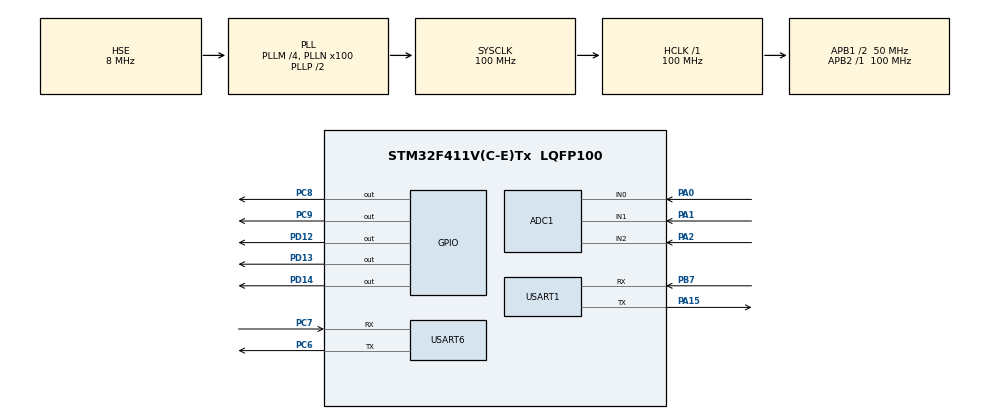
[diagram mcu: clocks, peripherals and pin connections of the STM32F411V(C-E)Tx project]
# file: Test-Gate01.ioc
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ADC1.Channel-0\#ChannelRegularConversion=ADC_CHANNEL_0
ADC1.Channel-1\#ChannelRegularConversion=ADC_CHANNEL_1
ADC1.Channel-2\#ChannelRegularConversion=ADC_CHANNEL_2
ADC1.Channel-3\#ChannelRegularConversion=ADC_CHANNEL_TEMPSENSOR
ADC1.Channel-4\#ChannelRegularConversion=ADC_CHANNEL_VREFINT
ADC1.ContinuousConvMode=ENABLE
ADC1.DMAContinuousRequests=ENABLE
ADC1.DiscontinuousConvMode=DISABLE
ADC1.NbrOfConversion=5
ADC1.NbrOfConversionFlag=1
ADC1.Rank-0\#ChannelRegularConversion=1
ADC1.Rank-1\#ChannelRegularConversion=2
ADC1.Rank-2\#ChannelRegularConversion=3
ADC1.Rank-3\#ChannelRegularConversion=4
ADC1.Rank-4\#ChannelRegularConversion=5
ADC1.SamplingTime-0\#ChannelRegularConversion=ADC_SAMPLETIME_480CYCLES
ADC1.SamplingTime-1\#ChannelRegularConversion=ADC_SAMPLETIME_480CYCLES
ADC1.SamplingTime-2\#ChannelRegularConversion=ADC_SAMPLETIME_480CYCLES
ADC1.SamplingTime-3\#ChannelRegularConversion=ADC_SAMPLETIME_480CYCLES
ADC1.SamplingTime-4\#ChannelRegularConversion=ADC_SAMPLETIME_480CYCLES
ADC1.ScanConvMode=ENABLE
ADC1.master=1
Dma.ADC1.3.Direction=DMA_PERIPH_TO_MEMORY
Dma.ADC1.3.FIFOMode=DMA_FIFOMODE_DISABLE
Dma.ADC1.3.Instance=DMA2_Stream0
Dma.ADC1.3.MemDataAlignment=DMA_MDATAALIGN_HALFWORD
Dma.ADC1.3.MemInc=DMA_MINC_ENABLE
Dma.ADC1.3.Mode=DMA_CIRCULAR
Dma.ADC1.3.PeriphDataAlignment=DMA_PDATAALIGN_HALFWORD
Dma.ADC1.3.PeriphInc=DMA_PINC_DISABLE
Dma.ADC1.3.Priority=DMA_PRIORITY_LOW
Dma.Request0=USART6_RX
Dma.Request1=USART6_TX
Dma.Request2=USART1_TX
Dma.Request3=ADC1
Dma.USART1_TX.2.Direction=DMA_MEMORY_TO_PERIPH
Dma.USART1_TX.2.FIFOMode=DMA_FIFOMODE_DISABLE
Dma.USART1_TX.2.Instance=DMA2_Stream7
Dma.USART1_TX.2.MemDataAlignment=DMA_MDATAALIGN_BYTE
Dma.USART1_TX.2.MemInc=DMA_MINC_ENABLE
Dma.USART1_TX.2.Mode=DMA_NORMAL
Dma.USART1_TX.2.PeriphDataAlignment=DMA_PDATAALIGN_BYTE
Dma.USART1_TX.2.PeriphInc=DMA_PINC_DISABLE
Dma.USART1_TX.2.Priority=DMA_PRIORITY_LOW
Dma.USART6_RX.0.Direction=DMA_PERIPH_TO_MEMORY
Dma.USART6_RX.0.FIFOMode=DMA_FIFOMODE_DISABLE
Dma.USART6_RX.0.Instance=DMA2_Stream1
Dma.USART6_RX.0.MemDataAlignment=DMA_MDATAALIGN_BYTE
Dma.USART6_RX.0.MemInc=DMA_MINC_ENABLE
Dma.USART6_RX.0.Mode=DMA_NORMAL
Dma.USART6_RX.0.PeriphDataAlignment=DMA_PDATAALIGN_BYTE
Dma.USART6_RX.0.PeriphInc=DMA_PINC_DISABLE
Dma.USART6_RX.0.Priority=DMA_PRIORITY_LOW
Dma.USART6_TX.1.Direction=DMA_MEMORY_TO_PERIPH
Dma.USART6_TX.1.FIFOMode=DMA_FIFOMODE_DISABLE
Dma.USART6_TX.1.Instance=DMA2_Stream6
Dma.USART6_TX.1.MemDataAlignment=DMA_MDATAALIGN_BYTE
Dma.USART6_TX.1.MemInc=DMA_MINC_ENABLE
Dma.USART6_TX.1.Mode=DMA_NORMAL
Dma.USART6_TX.1.PeriphDataAlignment=DMA_PDATAALIGN_BYTE
Dma.USART6_TX.1.PeriphInc=DMA_PINC_DISABLE
Dma.USART6_TX.1.Priority=DMA_PRIORITY_LOW
Mcu.Family=STM32F4
Mcu.Name=STM32F411V(C-E)Tx
Mcu.Package=LQFP100
NVIC.ADC_IRQn=true\:0\:0\:false\:false\:true\:true\:true\:true
NVIC.DMA2_Stream0_IRQn=true\:0\:0\:false\:false\:true\:false\:true\:true
NVIC.DMA2_Stream1_IRQn=true\:0\:0\:false\:false\:true\:false\:true\:true
NVIC.DMA2_Stream6_IRQn=true\:0\:0\:false\:false\:true\:false\:true\:true
NVIC.DMA2_Stream7_IRQn=true\:0\:0\:false\:false\:true\:false\:true\:true
NVIC.PriorityGroup=NVIC_PRIORITYGROUP_4
NVIC.TIM1_UP_TIM10_IRQn=true\:15\:0\:false\:false\:true\:false\:true\:true
NVIC.TimeBase=TIM1_UP_TIM10_IRQn
NVIC.TimeBaseIP=TIM1
NVIC.USART1_IRQn=true\:6\:0\:true\:false\:true\:true\:true\:true
NVIC.USART6_IRQn=true\:6\:0\:true\:false\:true\:false\:true\:true
PA0-WKUP.Signal=ADCx_IN0
PA1.Signal=ADCx_IN1
PA15.Mode=Asynchronous
PA15.Signal=USART1_TX
PA2.Signal=ADCx_IN2
PB7.Mode=Asynchronous
PB7.Signal=USART1_RX
PC6.Mode=Asynchronous
PC6.Signal=USART6_TX
PC7.Mode=Asynchronous
PC7.Signal=USART6_RX
PC8.Signal=GPIO_Output
PC9.Signal=GPIO_Output
PD12.Signal=GPIO_Output
PD13.Signal=GPIO_Output
PD14.Signal=GPIO_Output
PH0\ -\ OSC_IN.Mode=HSE-External-Oscillator
PH0\ -\ OSC_IN.Signal=RCC_OSC_IN
PH1\ -\ OSC_OUT.Mode=HSE-External-Oscillator
PH1\ -\ OSC_OUT.Signal=RCC_OSC_OUT
ProjectManager.HeapSize=0x200
ProjectManager.StackSize=0x400
ProjectManager.TargetToolchain=Makefile
RCC.48MHZClocksFreq_Value=50000000
RCC.AHBFreq_Value=100000000
RCC.APB1CLKDivider=RCC_HCLK_DIV2
RCC.APB1Freq_Value=50000000
RCC.APB1TimFreq_Value=100000000
RCC.APB2Freq_Value=100000000
RCC.APB2TimFreq_Value=100000000
RCC.CortexFreq_Value=100000000
RCC.HCLKFreq_Value=100000000
RCC.HSE_VALUE=8000000
RCC.HSI_VALUE=16000000
RCC.LSE_VALUE=32768
RCC.PLLM=4
RCC.PLLN=100
RCC.PLLSourceVirtual=RCC_PLLSOURCE_HSE
RCC.SYSCLKFreq_VALUE=100000000
RCC.SYSCLKSource=RCC_SYSCLKSOURCE_PLLCLK
RCC.VCOOutputFreq_Value=200000000
SH.ADCx_IN0.0=ADC1_IN0,IN0
SH.ADCx_IN1.0=ADC1_IN1,IN1
SH.ADCx_IN2.0=ADC1_IN2,IN2
USART1.VirtualMode=VM_ASYNC
USART6.VirtualMode=VM_ASYNC
VP_ADC1_TempSens_Input.Mode=IN-TempSens
VP_ADC1_Vref_Input.Mode=IN-Vrefint
VP_SYS_VS_tim1.Mode=TIM1
board=custom

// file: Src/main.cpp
/* USER CODE BEGIN Header */
/**
  ******************************************************************************
  * @file           : main.c
  * @brief          : Main program body
  ******************************************************************************
  * @attention
  *
  * Copyright (c) 2025 STMicroelectronics.
  * All rights reserved.
  *
  * This software is licensed under terms that can be found in the LICENSE file
  * in the root directory of this software component.
  * If no LICENSE file comes with this software, it is provided AS-IS.
  *
  ******************************************************************************
  */
/* USER CODE END Header */
#include "main.h"

/* USER CODE BEGIN Includes */
#include "task_handler.hpp"
#include "peripheral.hpp"
/* USER CODE END Includes */

ADC_HandleTypeDef hadc1;
DMA_HandleTypeDef hdma_adc1;

UART_HandleTypeDef huart1;
UART_HandleTypeDef huart6;
DMA_HandleTypeDef hdma_usart1_tx;
DMA_HandleTypeDef hdma_usart6_rx;
DMA_HandleTypeDef hdma_usart6_tx;

void SystemClock_Config(void);
static void MX_GPIO_Init(void);
static void MX_DMA_Init(void);
static void MX_USART1_UART_Init(void);
static void MX_USART6_UART_Init(void);
static void MX_ADC1_Init(void);

int main(void)
{

  /* USER CODE BEGIN 1 */
  BaseType_t status;
  /* USER CODE END 1 */

  /* MCU Configuration--------------------------------------------------------*/

  /* Reset of all peripherals, Initializes the Flash interface and the Systick. */
  HAL_Init();

  /* Configure the system clock */
  SystemClock_Config();

  /* Initialize all configured peripherals */
  MX_GPIO_Init();
  MX_DMA_Init();
  MX_USART1_UART_Init();
  MX_USART6_UART_Init();
  MX_ADC1_Init();
  /* USER CODE BEGIN 2 */
  firstInitializtion();
  /* USER CODE END 2 */

  /* Infinite loop */
  while (1)
  {

  }
}

void SystemClock_Config(void)
{
  RCC_OscInitTypeDef RCC_OscInitStruct = {0};
  RCC_ClkInitTypeDef RCC_ClkInitStruct = {0};

  /** Configure the main internal regulator output voltage
  */
  __HAL_RCC_PWR_CLK_ENABLE();
  __HAL_PWR_VOLTAGESCALING_CONFIG(PWR_REGULATOR_VOLTAGE_SCALE1);

  /** Initializes the RCC Oscillators according to the specified parameters
  * in the RCC_OscInitTypeDef structure.
  */
  RCC_OscInitStruct.OscillatorType = RCC_OSCILLATORTYPE_HSE;
  RCC_OscInitStruct.HSEState = RCC_HSE_ON;
  RCC_OscInitStruct.PLL.PLLState = RCC_PLL_ON;
  RCC_OscInitStruct.PLL.PLLSource = RCC_PLLSOURCE_HSE;
  RCC_OscInitStruct.PLL.PLLM = 4;
  RCC_OscInitStruct.PLL.PLLN = 100;
  RCC_OscInitStruct.PLL.PLLP = RCC_PLLP_DIV2;
  RCC_OscInitStruct.PLL.PLLQ = 4;
  if (HAL_RCC_OscConfig(&RCC_OscInitStruct) != HAL_OK)
  {
    Error_Handler();
  }

  /** Initializes the CPU, AHB and APB buses clocks
  */
  RCC_ClkInitStruct.ClockType = RCC_CLOCKTYPE_HCLK|RCC_CLOCKTYPE_SYSCLK
                              |RCC_CLOCKTYPE_PCLK1|RCC_CLOCKTYPE_PCLK2;
  RCC_ClkInitStruct.SYSCLKSource = RCC_SYSCLKSOURCE_PLLCLK;
  RCC_ClkInitStruct.AHBCLKDivider = RCC_SYSCLK_DIV1;
  RCC_ClkInitStruct.APB1CLKDivider = RCC_HCLK_DIV2;
  RCC_ClkInitStruct.APB2CLKDivider = RCC_HCLK_DIV1;

  if (HAL_RCC_ClockConfig(&RCC_ClkInitStruct, FLASH_LATENCY_3) != HAL_OK)
  {
    Error_Handler();
  }
}

static void MX_ADC1_Init(void)
{

  ADC_ChannelConfTypeDef sConfig = {0};

  /** Configure the global features of the ADC (Clock, Resolution, Data Alignment and number of conversion)
  */
  hadc1.Instance = ADC1;
  hadc1.Init.ClockPrescaler = ADC_CLOCK_SYNC_PCLK_DIV4;
  hadc1.Init.Resolution = ADC_RESOLUTION_12B;
  hadc1.Init.ScanConvMode = ENABLE;
  hadc1.Init.ContinuousConvMode = ENABLE;
  hadc1.Init.DiscontinuousConvMode = DISABLE;
  hadc1.Init.ExternalTrigConvEdge = ADC_EXTERNALTRIGCONVEDGE_NONE;
  hadc1.Init.ExternalTrigConv = ADC_SOFTWARE_START;
  hadc1.Init.DataAlign = ADC_DATAALIGN_RIGHT;
  hadc1.Init.NbrOfConversion = 5;
  hadc1.Init.DMAContinuousRequests = ENABLE;
  hadc1.Init.EOCSelection = ADC_EOC_SINGLE_CONV;
  if (HAL_ADC_Init(&hadc1) != HAL_OK)
  {
    Error_Handler();
  }

  /** Configure for the selected ADC regular channel its corresponding rank in the sequencer and its sample time.
  */
  sConfig.Channel = ADC_CHANNEL_0;
  sConfig.Rank = 1;
  sConfig.SamplingTime = ADC_SAMPLETIME_480CYCLES;
  if (HAL_ADC_ConfigChannel(&hadc1, &sConfig) != HAL_OK)
  {
    Error_Handler();
  }

  /** Configure for the selected ADC regular channel its corresponding rank in the sequencer and its sample time.
  */
  sConfig.Channel = ADC_CHANNEL_1;
  sConfig.Rank = 2;
  if (HAL_ADC_ConfigChannel(&hadc1, &sConfig) != HAL_OK)
  {
    Error_Handler();
  }

  /** Configure for the selected ADC regular channel its corresponding rank in the sequencer and its sample time.
  */
  sConfig.Channel = ADC_CHANNEL_2;
  sConfig.Rank = 3;
  if (HAL_ADC_ConfigChannel(&hadc1, &sConfig) != HAL_OK)
  {
    Error_Handler();
  }

  /** Configure for the selected ADC regular channel its corresponding rank in the sequencer and its sample time.
  */
  sConfig.Channel = ADC_CHANNEL_TEMPSENSOR;
  sConfig.Rank = 4;
  if (HAL_ADC_ConfigChannel(&hadc1, &sConfig) != HAL_OK)
  {
    Error_Handler();
  }

  /** Configure for the selected ADC regular channel its corresponding rank in the sequencer and its sample time.
  */
  sConfig.Channel = ADC_CHANNEL_VREFINT;
  sConfig.Rank = 5;
  if (HAL_ADC_ConfigChannel(&hadc1, &sConfig) != HAL_OK)
  {
    Error_Handler();
  }

}

static void MX_USART1_UART_Init(void)
{

  huart1.Instance = USART1;
  huart1.Init.BaudRate = 115200;
  huart1.Init.WordLength = UART_WORDLENGTH_8B;
  huart1.Init.StopBits = UART_STOPBITS_1;
  huart1.Init.Parity = UART_PARITY_NONE;
  huart1.Init.Mode = UART_MODE_TX_RX;
  huart1.Init.HwFlowCtl = UART_HWCONTROL_NONE;
  huart1.Init.OverSampling = UART_OVERSAMPLING_16;
  if (HAL_UART_Init(&huart1) != HAL_OK)
  {
    Error_Handler();
  }

}

static void MX_USART6_UART_Init(void)
{

  huart6.Instance = USART6;
  huart6.Init.BaudRate = 57600;
  huart6.Init.WordLength = UART_WORDLENGTH_8B;
  huart6.Init.StopBits = UART_STOPBITS_1;
  huart6.Init.Parity = UART_PARITY_NONE;
  huart6.Init.Mode = UART_MODE_TX_RX;
  huart6.Init.HwFlowCtl = UART_HWCONTROL_NONE;
  huart6.Init.OverSampling = UART_OVERSAMPLING_16;
  if (HAL_UART_Init(&huart6) != HAL_OK)
  {
    Error_Handler();
  }

}

static void MX_DMA_Init(void)
{

  /* DMA controller clock enable */
  __HAL_RCC_DMA2_CLK_ENABLE();

  /* DMA interrupt init */
  /* DMA2_Stream0_IRQn interrupt configuration */
  HAL_NVIC_SetPriority(DMA2_Stream0_IRQn, 6, 0);
  HAL_NVIC_EnableIRQ(DMA2_Stream0_IRQn);
  /* DMA2_Stream1_IRQn interrupt configuration */
  HAL_NVIC_SetPriority(DMA2_Stream1_IRQn, 6, 0);
  HAL_NVIC_EnableIRQ(DMA2_Stream1_IRQn);
  /* DMA2_Stream6_IRQn interrupt configuration */
  HAL_NVIC_SetPriority(DMA2_Stream6_IRQn, 6, 0);
  HAL_NVIC_EnableIRQ(DMA2_Stream6_IRQn);
  /* DMA2_Stream7_IRQn interrupt configuration */
  HAL_NVIC_SetPriority(DMA2_Stream7_IRQn, 6, 0);
  HAL_NVIC_EnableIRQ(DMA2_Stream7_IRQn);

}

static void MX_GPIO_Init(void)
{
  GPIO_InitTypeDef GPIO_InitStruct = {0};

  /* GPIO Ports Clock Enable */
  __HAL_RCC_GPIOH_CLK_ENABLE();
  __HAL_RCC_GPIOA_CLK_ENABLE();
  __HAL_RCC_GPIOD_CLK_ENABLE();
  __HAL_RCC_GPIOC_CLK_ENABLE();
  __HAL_RCC_GPIOB_CLK_ENABLE();

  /*Configure GPIO pin Output Level */
  HAL_GPIO_WritePin(GPIOD, GPIO_PIN_12|GPIO_PIN_13|GPIO_PIN_14|GPIO_PIN_15, GPIO_PIN_RESET);

  /*Configure GPIO pin Output Level */
  HAL_GPIO_WritePin(GPIOC, GPIO_PIN_8|GPIO_PIN_9, GPIO_PIN_RESET);

  /*Configure GPIO pins : PD12 PD13 PD14 */
  GPIO_InitStruct.Pin = GPIO_PIN_12|GPIO_PIN_13|GPIO_PIN_14|GPIO_PIN_15;
  GPIO_InitStruct.Mode = GPIO_MODE_OUTPUT_PP;
  GPIO_InitStruct.Pull = GPIO_NOPULL;
  GPIO_InitStruct.Speed = GPIO_SPEED_FREQ_LOW;
  HAL_GPIO_Init(GPIOD, &GPIO_InitStruct);

  /*Configure GPIO pins : PC8 PC9 */
  GPIO_InitStruct.Pin = GPIO_PIN_8|GPIO_PIN_9;
  GPIO_InitStruct.Mode = GPIO_MODE_OUTPUT_PP;
  GPIO_InitStruct.Pull = GPIO_NOPULL;
  GPIO_InitStruct.Speed = GPIO_SPEED_FREQ_LOW;
  HAL_GPIO_Init(GPIOC, &GPIO_InitStruct);

}

void HAL_TIM_PeriodElapsedCallback(TIM_HandleTypeDef *htim)
{
  if (htim->Instance == TIM1) {
    HAL_IncTick();
  }
}

void Error_Handler(void)
{
  __disable_irq();
  while (1)
  {
  }
}
